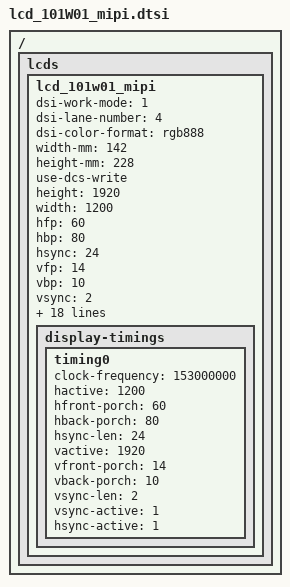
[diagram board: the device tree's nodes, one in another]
// SPDX-License-Identifier: GPL-2.0

/ { lcds: lcds {
	 lcd_101w01_mipi: lcd_101w01_mipi {
		dsi-work-mode = <1>; /* video burst mode*/
		dsi-lane-number = <4>;
		dsi-color-format = "rgb888";
		width-mm = <142>;
		height-mm = <228>;
		use-dcs-write;

		/*mipi info*/
		height = <1920>;
		width = <1200>;
		hfp = <60>;
		hbp = <80>;
		hsync = <24>;
		vfp = <14>;
		vbp = <10>;
		vsync = <2>;
		fps = <60>;
		work-mode = <0>;
		rgb-mode = <3>;
		lane-number = <4>;
		phy-bit-clock = <1000000000>;
		phy-esc-clock = <76800000>;
		split-enable = <0>;
		eotp-enable = <0>;
		burst-mode = <2>;
		esd-check-enable = <0>;

		/* DSI_CMD, DSI_MODE, timeout, len, cmd */
		initial-command = [
			39 01 00 02 B0 01
			39 01 00 02 C0 26
			39 01 00 02 C1 10
			39 01 00 02 C2 0E
			39 01 00 02 C3 00
			39 01 00 02 C4 00
			39 01 00 02 C5 23
			39 01 00 02 C6 11
			39 01 00 02 C7 22
			39 01 00 02 C8 20
			39 01 00 02 C9 1E
			39 01 00 02 CA 1C
			39 01 00 02 CB 0C
			39 01 00 02 CC 0A
			39 01 00 02 CD 08
			39 01 00 02 CE 06
			39 01 00 02 CF 18
			39 01 00 02 D0 02
			39 01 00 02 D1 00
			39 01 00 02 D2 00
			39 01 00 02 D3 00
			39 01 00 02 D4 26
			39 01 00 02 D5 0F
			39 01 00 02 D6 0D
			39 01 00 02 D7 00
			39 01 00 02 D8 00
			39 01 00 02 D9 23
			39 01 00 02 DA 11
			39 01 00 02 DB 21
			39 01 00 02 DC 1F
			39 01 00 02 DD 1D
			39 01 00 02 DE 1B
			39 01 00 02 DF 0B
			39 01 00 02 E0 09
			39 01 00 02 E1 07
			39 01 00 02 E2 05
			39 01 00 02 E3 17
			39 01 00 02 E4 01
			39 01 00 02 E5 00
			39 01 00 02 E6 00
			39 01 00 02 E7 00
			39 01 00 02 B0 02
			39 01 00 02 C0 00
			39 01 00 02 C1 12
			39 01 00 02 C2 1b
			39 01 00 02 C3 1A
			39 01 00 02 C4 37
			39 01 00 02 C5 3A
			39 01 00 02 C6 3C
			39 01 00 02 C7 3D
			39 01 00 02 C8 3A
			39 01 00 02 C9 33
			39 01 00 02 CA 30
			39 01 00 02 CB 30
			39 01 00 02 CC 32
			39 01 00 02 CD 2A
			39 01 00 02 CE 2D
			39 01 00 02 CF 2F
			39 01 00 02 D2 00
			39 01 00 02 D3 12
			39 01 00 02 D4 1B
			39 01 00 02 D5 1A
			39 01 00 02 D6 37
			39 01 00 02 D7 3A
			39 01 00 02 D8 3C
			39 01 00 02 D9 3D
			39 01 00 02 DA 3A
			39 01 00 02 DB 33
			39 01 00 02 DC 30
			39 01 00 02 DD 30
			39 01 00 02 DE 32
			39 01 00 02 DF 2A
			39 01 00 02 E0 2D
			39 01 00 02 E1 2F
			39 01 00 02 E2 07
			39 01 00 02 B0 03
			39 01 00 02 BE 04
			39 01 00 02 B9 40
			39 01 00 02 CC 88
			39 01 00 02 C8 0C
			39 01 00 02 C9 07
			39 01 00 02 CD 01
			39 01 00 02 CA 40
			39 01 00 02 CE 1A
			39 01 00 02 CF 60
			39 01 00 02 D2 08
			39 01 00 02 D3 08
			39 01 00 02 DB 01
			39 01 00 02 D9 06
			39 01 00 02 D4 00
			39 01 00 02 D5 01
			39 01 00 02 D6 04
			39 01 00 02 D7 03
			39 01 00 02 C2 00
			39 01 00 02 C3 0E
			39 01 00 02 C4 00
			39 01 00 02 C5 0E
			39 01 00 02 DD 00
			39 01 00 02 DE 0E
			39 01 00 02 E6 00
			39 01 00 02 E7 0E
			39 01 00 02 C2 00
			39 01 00 02 C3 0E
			39 01 00 02 C4 00
			39 01 00 02 C5 0E
			39 01 00 02 DD 00
			39 01 00 02 DE 0E
			39 01 00 02 E6 00
			39 01 00 02 E7 0E
			39 01 00 02 B0 06
			39 01 00 02 C0 A5
			39 01 00 02 D5 1C
			39 01 00 02 C0 00
			39 01 00 02 B0 00
			39 01 00 02 BA 8F
			39 01 00 02 F9 5C
			39 01 00 02 C2 14
			39 01 00 02 C4 14
			39 01 00 02 BF 1A
			39 01 00 02 C0 11
			39 01 78 01 11
			39 01 1E 01 29
		];
		sleep-in-command = [
			39 01 78 01 28
			39 01 78 01 10
		];
		sleep-out-command = [
			39 01 96 01 11
			39 01 32 01 29
		];
		read-id-command = [
			37 01 00 01 05
			14 01 00 05 fb fc fd fe ff
		];

		display-timings {
			timing0 {
				clock-frequency = <153000000>;
				hactive = <1200>;
				hfront-porch = <60>;
				hback-porch = <80>;
				hsync-len = <24>;
				vactive = <1920>;
				vfront-porch = <14>;
				vback-porch = <10>;
				vsync-len = <2>;
				vsync-active = <1>;
				hsync-active = <1>;
			};
		};
	};
};};
